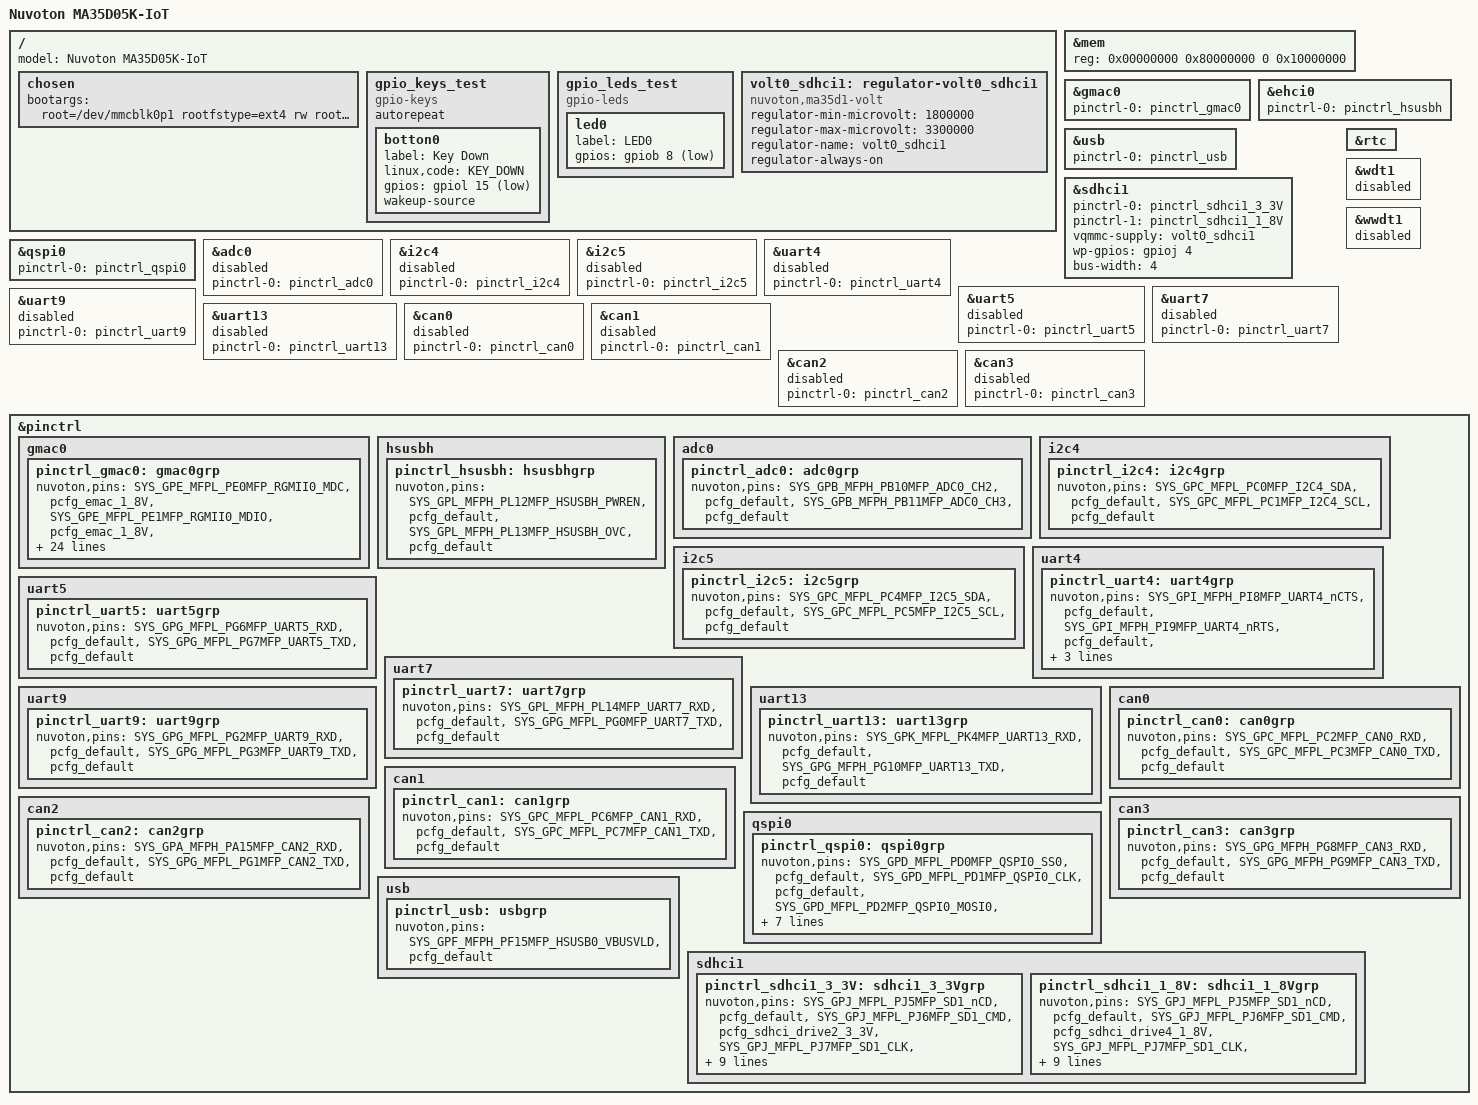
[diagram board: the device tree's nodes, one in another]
/*
 * Device Tree Source for MA35D0 IoT Board
 *
 * Copyright (C) 2021 Nuvoton Technology Corp.
 *
 * The code contained herein is licensed under the GNU General Public
 * License. You may obtain a copy of the GNU General Public License
 * Version 2 or later at the following locations:
 *
 * http://www.opensource.org/licenses/gpl-license.html
 * http://www.gnu.org/copyleft/gpl.html
 */

/dts-v1/;

#include "ma35d05k.dtsi"

/ {
	model = "Nuvoton MA35D05K-IoT";

	chosen {
		bootargs = "root=/dev/mmcblk0p1 rootfstype=ext4 rw rootwait console=ttyS0,115200n8 rdinit=/sbin/init mem=256M";
	};

	gpio_keys_test {
		compatible = "gpio-keys";
		status = "okay";
		autorepeat;
		botton0 {
			label = "Key Down";
			linux,code = <KEY_DOWN>;
			gpios = <&gpiol 15 GPIO_ACTIVE_LOW>;
			wakeup-source;
		};
	};

	gpio_leds_test {
		compatible = "gpio-leds";
		status = "okay";
		led0 {
			label = "LED0";
			gpios = <&gpiob 8 GPIO_ACTIVE_LOW>;
		};
	};

	volt0_sdhci1: regulator-volt0_sdhci1 {
		compatible = "nuvoton,ma35d1-volt";
		regulator-min-microvolt = <1800000>;
		regulator-max-microvolt = <3300000>;
		regulator-name = "volt0_sdhci1";
		regulator-always-on;
	};
};

&mem {
	device_type = "memory";
	reg = <0x00000000 0x80000000 0 0x10000000>; /* DRAM space - 1, size : 256MB DRAM */
};

&gmac0 {
	status = "okay";
	pinctrl-names = "default";
	pinctrl-0 = <&pinctrl_gmac0>;
};

&ehci0 {
	pinctrl-names = "default";
	pinctrl-0 = <&pinctrl_hsusbh>;
};

&usb {
	pinctrl-names = "default";
	pinctrl-0 = <&pinctrl_usb>;
};


&sdhci1 {
	status = "okay";
	pinctrl-names = "sdhci_3V3","sdhci_1V8";
	pinctrl-0 = <&pinctrl_sdhci1_3_3V>;
	pinctrl-1 = <&pinctrl_sdhci1_1_8V>;
	vqmmc-supply = <&volt0_sdhci1>;
	wp-gpios = <&gpioj 4 GPIO_ACTIVE_HIGH>;
	bus-width = <4>;
};

&qspi0 {
	status = "okay";
	pinctrl-names = "default";
	pinctrl-0 = <&pinctrl_qspi0>;
};

/*
 * CON2 and CON3 expose these interfaces without populated peripherals.
 * Keep the controllers disabled until the required external device or CAN
 * transceiver is connected.
 */
&adc0 {
	status = "disabled";
	pinctrl-names = "default";
	pinctrl-0 = <&pinctrl_adc0>;
	/delete-property/ enable-ts;
	/delete-property/ ts-type;
};

&i2c4 {
	status = "disabled";
	pinctrl-names = "default";
	pinctrl-0 = <&pinctrl_i2c4>;
};

&i2c5 {
	status = "disabled";
	pinctrl-names = "default";
	pinctrl-0 = <&pinctrl_i2c5>;
};

&uart4 {
	status = "disabled";
	pinctrl-names = "default";
	pinctrl-0 = <&pinctrl_uart4>;
};

&uart5 {
	status = "disabled";
	pinctrl-names = "default";
	pinctrl-0 = <&pinctrl_uart5>;
};

&uart7 {
	status = "disabled";
	pinctrl-names = "default";
	pinctrl-0 = <&pinctrl_uart7>;
};

&uart9 {
	status = "disabled";
	pinctrl-names = "default";
	pinctrl-0 = <&pinctrl_uart9>;
};

&uart13 {
	status = "disabled";
	pinctrl-names = "default";
	pinctrl-0 = <&pinctrl_uart13>;
};

&can0 {
	status = "disabled";
	pinctrl-names = "default";
	pinctrl-0 = <&pinctrl_can0>;
};

&can1 {
	status = "disabled";
	pinctrl-names = "default";
	pinctrl-0 = <&pinctrl_can1>;
};

&can2 {
	status = "disabled";
	pinctrl-names = "default";
	pinctrl-0 = <&pinctrl_can2>;
};

&can3 {
	status = "disabled";
	pinctrl-names = "default";
	pinctrl-0 = <&pinctrl_can3>;
};

&rtc {
	status = "okay";
};

/* Enable a watchdog only when the system has a watchdog service policy. */
&wdt1 {
	status = "disabled";
};

&wwdt1 {
	status = "disabled";
};

&pinctrl {
	gmac0 {
		pinctrl_gmac0: gmac0grp{
			nuvoton,pins =
				<SYS_GPE_MFPL_PE0MFP_RGMII0_MDC		&pcfg_emac_1_8V>,
				<SYS_GPE_MFPL_PE1MFP_RGMII0_MDIO	&pcfg_emac_1_8V>,
				<SYS_GPE_MFPL_PE2MFP_RGMII0_TXCTL	&pcfg_emac_1_8V>,
				<SYS_GPE_MFPL_PE3MFP_RGMII0_TXD0	&pcfg_emac_1_8V>,
				<SYS_GPE_MFPL_PE4MFP_RGMII0_TXD1	&pcfg_emac_1_8V>,
				<SYS_GPE_MFPL_PE5MFP_RGMII0_RXCLK	&pcfg_emac_1_8V>,
				<SYS_GPE_MFPL_PE6MFP_RGMII0_RXCTL	&pcfg_emac_1_8V>,
				<SYS_GPE_MFPL_PE7MFP_RGMII0_RXD0	&pcfg_emac_1_8V>,
				<SYS_GPE_MFPH_PE8MFP_RGMII0_RXD1	&pcfg_emac_1_8V>,
				<SYS_GPE_MFPH_PE9MFP_RGMII0_RXD2	&pcfg_emac_1_8V>,
				<SYS_GPF_MFPL_PF0MFP_RGMII0_RXD3	&pcfg_emac_1_8V>,
				<SYS_GPF_MFPL_PF1MFP_RGMII0_TXCLK	&pcfg_emac_1_8V>,
				<SYS_GPF_MFPL_PF2MFP_RGMII0_TXD2	&pcfg_emac_1_8V>,
				<SYS_GPF_MFPL_PF3MFP_RGMII0_TXD3	&pcfg_emac_1_8V>;
		};
	};

	hsusbh {
		pinctrl_hsusbh: hsusbhgrp{
			nuvoton,pins =
				<SYS_GPL_MFPH_PL12MFP_HSUSBH_PWREN	&pcfg_default>,
				<SYS_GPL_MFPH_PL13MFP_HSUSBH_OVC	&pcfg_default>;
		};
	};

	adc0 {
		pinctrl_adc0: adc0grp {
			nuvoton,pins =
				<SYS_GPB_MFPH_PB10MFP_ADC0_CH2	&pcfg_default>,
				<SYS_GPB_MFPH_PB11MFP_ADC0_CH3	&pcfg_default>;
		};
	};

	i2c4 {
		pinctrl_i2c4: i2c4grp {
			nuvoton,pins =
				<SYS_GPC_MFPL_PC0MFP_I2C4_SDA	&pcfg_default>,
				<SYS_GPC_MFPL_PC1MFP_I2C4_SCL	&pcfg_default>;
		};
	};

	i2c5 {
		pinctrl_i2c5: i2c5grp {
			nuvoton,pins =
				<SYS_GPC_MFPL_PC4MFP_I2C5_SDA	&pcfg_default>,
				<SYS_GPC_MFPL_PC5MFP_I2C5_SCL	&pcfg_default>;
		};
	};

	uart4 {
		pinctrl_uart4: uart4grp {
			nuvoton,pins =
				<SYS_GPI_MFPH_PI8MFP_UART4_nCTS	&pcfg_default>,
				<SYS_GPI_MFPH_PI9MFP_UART4_nRTS	&pcfg_default>,
				<SYS_GPI_MFPH_PI10MFP_UART4_RXD	&pcfg_default>,
				<SYS_GPI_MFPH_PI11MFP_UART4_TXD	&pcfg_default>;
		};
	};

	uart5 {
		pinctrl_uart5: uart5grp {
			nuvoton,pins =
				<SYS_GPG_MFPL_PG6MFP_UART5_RXD	&pcfg_default>,
				<SYS_GPG_MFPL_PG7MFP_UART5_TXD	&pcfg_default>;
		};
	};

	uart7 {
		pinctrl_uart7: uart7grp {
			nuvoton,pins =
				<SYS_GPL_MFPH_PL14MFP_UART7_RXD	&pcfg_default>,
				<SYS_GPG_MFPL_PG0MFP_UART7_TXD	&pcfg_default>;
		};
	};

	uart9 {
		pinctrl_uart9: uart9grp {
			nuvoton,pins =
				<SYS_GPG_MFPL_PG2MFP_UART9_RXD	&pcfg_default>,
				<SYS_GPG_MFPL_PG3MFP_UART9_TXD	&pcfg_default>;
		};
	};

	uart13 {
		pinctrl_uart13: uart13grp {
			nuvoton,pins =
				<SYS_GPK_MFPL_PK4MFP_UART13_RXD	&pcfg_default>,
				<SYS_GPG_MFPH_PG10MFP_UART13_TXD	&pcfg_default>;
		};
	};

	can0 {
		pinctrl_can0: can0grp {
			nuvoton,pins =
				<SYS_GPC_MFPL_PC2MFP_CAN0_RXD	&pcfg_default>,
				<SYS_GPC_MFPL_PC3MFP_CAN0_TXD	&pcfg_default>;
		};
	};

	can1 {
		pinctrl_can1: can1grp {
			nuvoton,pins =
				<SYS_GPC_MFPL_PC6MFP_CAN1_RXD	&pcfg_default>,
				<SYS_GPC_MFPL_PC7MFP_CAN1_TXD	&pcfg_default>;
		};
	};

	can2 {
		pinctrl_can2: can2grp {
			nuvoton,pins =
				<SYS_GPA_MFPH_PA15MFP_CAN2_RXD	&pcfg_default>,
				<SYS_GPG_MFPL_PG1MFP_CAN2_TXD	&pcfg_default>;
		};
	};

	can3 {
		pinctrl_can3: can3grp {
			nuvoton,pins =
				<SYS_GPG_MFPH_PG8MFP_CAN3_RXD	&pcfg_default>,
				<SYS_GPG_MFPH_PG9MFP_CAN3_TXD	&pcfg_default>;
		};
	};

	qspi0 {
		pinctrl_qspi0: qspi0grp{
			nuvoton,pins =
				<SYS_GPD_MFPL_PD0MFP_QSPI0_SS0		&pcfg_default>,
				<SYS_GPD_MFPL_PD1MFP_QSPI0_CLK		&pcfg_default>,
				<SYS_GPD_MFPL_PD2MFP_QSPI0_MOSI0	&pcfg_default>,
				<SYS_GPD_MFPL_PD3MFP_QSPI0_MISO0	&pcfg_default>,
				<SYS_GPD_MFPL_PD4MFP_QSPI0_MOSI1	&pcfg_default>,
				<SYS_GPD_MFPL_PD5MFP_QSPI0_MISO1	&pcfg_default>;
		};
	};

	usb {
		pinctrl_usb: usbgrp{
			nuvoton,pins =
				<SYS_GPF_MFPH_PF15MFP_HSUSB0_VBUSVLD	&pcfg_default>;
		};
	};

	sdhci1 {
		pinctrl_sdhci1_3_3V: sdhci1_3_3Vgrp{
			nuvoton,pins =
				<SYS_GPJ_MFPL_PJ5MFP_SD1_nCD	&pcfg_default>,
				<SYS_GPJ_MFPL_PJ6MFP_SD1_CMD	&pcfg_sdhci_drive2_3_3V>,
				<SYS_GPJ_MFPL_PJ7MFP_SD1_CLK	&pcfg_sdhci_drive2_3_3V>,
				<SYS_GPJ_MFPH_PJ8MFP_SD1_DAT0	&pcfg_sdhci_drive2_3_3V>,
				<SYS_GPJ_MFPH_PJ9MFP_SD1_DAT1	&pcfg_sdhci_drive2_3_3V>,
				<SYS_GPJ_MFPH_PJ10MFP_SD1_DAT2	&pcfg_sdhci_drive2_3_3V>,
				<SYS_GPJ_MFPH_PJ11MFP_SD1_DAT3	&pcfg_sdhci_drive2_3_3V>;
		};

		pinctrl_sdhci1_1_8V: sdhci1_1_8Vgrp{
			nuvoton,pins =
				<SYS_GPJ_MFPL_PJ5MFP_SD1_nCD	&pcfg_default>,
				<SYS_GPJ_MFPL_PJ6MFP_SD1_CMD	&pcfg_sdhci_drive4_1_8V>,
				<SYS_GPJ_MFPL_PJ7MFP_SD1_CLK	&pcfg_sdhci_drive7_1_8V>,
				<SYS_GPJ_MFPH_PJ8MFP_SD1_DAT0	&pcfg_sdhci_drive1_1_8V>,
				<SYS_GPJ_MFPH_PJ9MFP_SD1_DAT1	&pcfg_sdhci_drive1_1_8V>,
				<SYS_GPJ_MFPH_PJ10MFP_SD1_DAT2	&pcfg_sdhci_drive1_1_8V>,
				<SYS_GPJ_MFPH_PJ11MFP_SD1_DAT3	&pcfg_sdhci_drive1_1_8V>;
		};
	};
};
